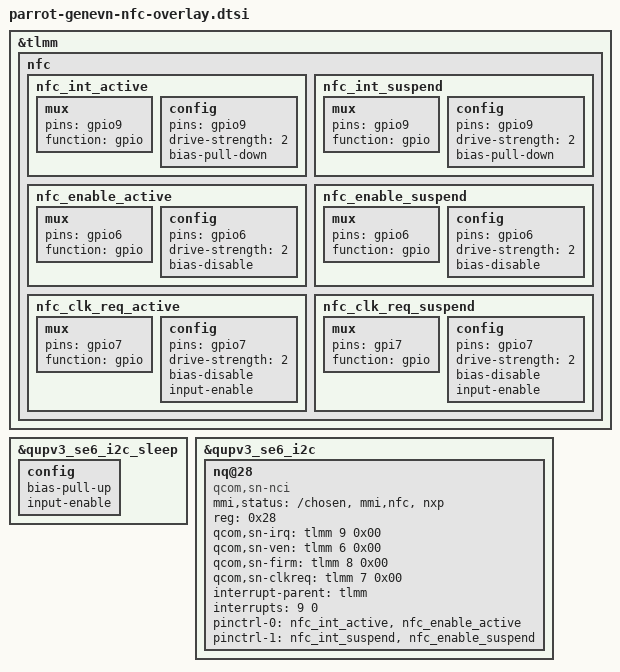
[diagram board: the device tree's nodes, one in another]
/* Copyright (c) 2021, The Linux Foundation. All rights reserved.
 *
 * This program is free software; you can redistribute it and/or modify
 * it under the terms of the GNU General Public License version 2 and
 * only version 2 as published by the Free Software Foundation.
 *
 * This program is distributed in the hope that it will be useful,
 * but WITHOUT ANY WARRANTY; without even the implied warranty of
 * MERCHANTABILITY or FITNESS FOR A PARTICULAR PURPOSE.  See the
 * GNU General Public License for more details.
 */

&tlmm {
	nfc {
		nfc_int_active: nfc_int_active {
			/* active state */
			mux {
				/* NFC Read Interrupt */
				pins = "gpio9";
				function = "gpio";
			};

			config {
				pins = "gpio9";
				drive-strength = <2>; /* 2 MA */
				bias-pull-down;
			};
		};

		nfc_int_suspend: nfc_int_suspend {
			/* sleep state */
			mux {
				/* NFC Read Interrupt */
				pins = "gpio9";
				function = "gpio";
			};

			config {
				pins = "gpio9";
				drive-strength = <2>; /* 2 MA */
				bias-pull-down;
			};
		};

		nfc_enable_active: nfc_enable_active {
			mux {
				pins = "gpio6";
				function = "gpio";
			};

			config {
				pins = "gpio6";
				drive-strength = <2>; /* 2 MA */
				bias-disable;
			};
		};

		nfc_enable_suspend: nfc_enable_suspend {
			mux {
				pins = "gpio6";
				function = "gpio";
			};

			config {
				pins = "gpio6";
				drive-strength = <2>; /* 2 MA */
				bias-disable;
			};
		};


		nfc_clk_req_active: nfc_clk_req_active {
			/* active state */
			mux {
				/* GPIO 7: NFC CLK Req*/
				pins = "gpio7";
				function = "gpio";
			};

			config {
				pins = "gpio7";
				drive-strength = <2>; /* 2 MA */
				bias-disable;
				input-enable;
			};
		};

		nfc_clk_req_suspend: nfc_clk_req_suspend {
			/* sleep state */
			mux {
				/* GPIO 7: NFC CLK Req */
				pins = "gpi7";
				function = "gpio";
			};

			config {
				pins = "gpio7";
				drive-strength = <2>; /* 2 MA */
				bias-disable;
				input-enable;
			};
		};
	};
};

&qupv3_se6_i2c_sleep {
    config {
        /delete-property/ bias-disable;
        bias-pull-up;
        input-enable;
    };
};

&qupv3_se6_i2c {
	status = "ok";
	#address-cells = <1>;
	#size-cells = <0>;
	nq@28 {
		compatible = "qcom,sn-nci";
		mmi,status = "/chosen", "mmi,nfc", "nxp";
		reg = <0x28>;
		qcom,sn-irq = <&tlmm 9 0x00>;
		qcom,sn-ven = <&tlmm 6 0x00>;
		qcom,sn-firm = <&tlmm 8 0x00>;
		qcom,sn-clkreq = <&tlmm 7 0x00>;
		interrupt-parent = <&tlmm>;
		interrupts = <9 0>;
		interrupt-names = "nfc_irq";
		pinctrl-names = "nfc_active", "nfc_suspend";
		pinctrl-0 = <&nfc_int_active &nfc_enable_active>;
		pinctrl-1 = <&nfc_int_suspend &nfc_enable_suspend>;
	};
};

